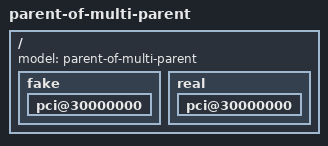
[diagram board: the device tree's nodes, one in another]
/dts-v1/;
/ {
    #address-cells = <2>;
    #size-cells = <2>;
    model = "parent-of-multi-parent";

    fake {
        #address-cells = <1>;
        #size-cells = <1>;
        pci@30000000 {
            device_type = "pci";
            #address-cells = <3>;
            #size-cells = <2>;
            ranges = <0x2000000 0x0 0x40000000 0x0 0x40000000 0x0 0x40000000
                      0x3000000 0x4 0x0      0x4 0x0      0x4 0x0
                      0x1000000 0x0 0x0      0x0 0x3000000 0x0 0x10000
                      0x2000000 0x0 0x50000000 0x0 0x50000000 0x0 0x20000000
                      0x2000000 0x0 0x70000000 0x0 0x70000000 0x0 0x10000000
                      0x1000000 0x0 0x0      0x0 0x3000000 0x0 0x10000>;
        };
    };

    real {
        #address-cells = <2>;
        #size-cells = <2>;
        pci@30000000 {
            device_type = "pci";
            #address-cells = <3>;
            #size-cells = <2>;
            ranges = <0x2000000 0x0 0x40000000 0x0 0x40000000 0x0 0x40000000
                      0x3000000 0x4 0x0      0x4 0x0      0x4 0x0
                      0x1000000 0x0 0x0      0x0 0x3000000 0x0 0x10000
                      0x2000000 0x0 0x50000000 0x0 0x50000000 0x0 0x20000000
                      0x2000000 0x0 0x70000000 0x0 0x70000000 0x0 0x10000000
                      0x1000000 0x0 0x0      0x0 0x3000000 0x0 0x10000>;
        };
    };
};
